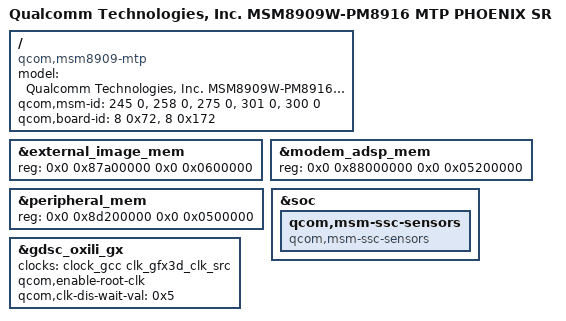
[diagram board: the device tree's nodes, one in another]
/*
 * Copyright (c) 2015-2016, The Linux Foundation. All rights reserved.
 *
 * This program is free software; you can redistribute it and/or modify
 * it under the terms of the GNU General Public License version 2 and
 * only version 2 as published by the Free Software Foundation.
 *
 * This program is distributed in the hope that it will be useful,
 * but WITHOUT ANY WARRANTY; without even the implied warranty of
 * MERCHANTABILITY or FITNESS FOR A PARTICULAR PURPOSE.  See the
 * GNU General Public License for more details.
 */

/dts-v1/;

#include "phoenix-sr_msm8909-mtp.dtsi"
#include "phoenix-sr_msm8909w-gpu.dtsi"
#include "phoenix-sr_msm8909-pm8916.dtsi"
#include "phoenix-sr_msm8909-pm8916-mtp.dtsi"
#include "phoenix-sr_msm8909w.dtsi"

/ {
	model = "Qualcomm Technologies, Inc. MSM8909W-PM8916 MTP PHOENIX SR";
	compatible = "qcom,msm8909-mtp", "qcom,msm8909", "qcom,mtp";
	qcom,msm-id =   <245 0>,
			<258 0>,
			<275 0>,
			<301 0>, /*force for apq8009w evb2 board */
			<300 0>;
	qcom,board-id= <8 0x72>,<8 0x172>; /*0x172 force for apq8009w evb2 board*/
};

&external_image_mem {
	reg = <0x0 0x87a00000 0x0 0x0600000>;
};

&modem_adsp_mem {
	reg = <0x0 0x88000000 0x0 0x05200000>;
};

&peripheral_mem {
	reg = <0x0 0x8d200000 0x0 0x0500000>;
};

&soc {
	qcom,msm-ssc-sensors {
		compatible = "qcom,msm-ssc-sensors";
	};
};

&gdsc_oxili_gx {
	clock-names = "core_root_clk";
	clocks =<&clock_gcc clk_gfx3d_clk_src>;
	qcom,enable-root-clk;
	qcom,clk-dis-wait-val = <0x5>;
	status = "okay";
};
